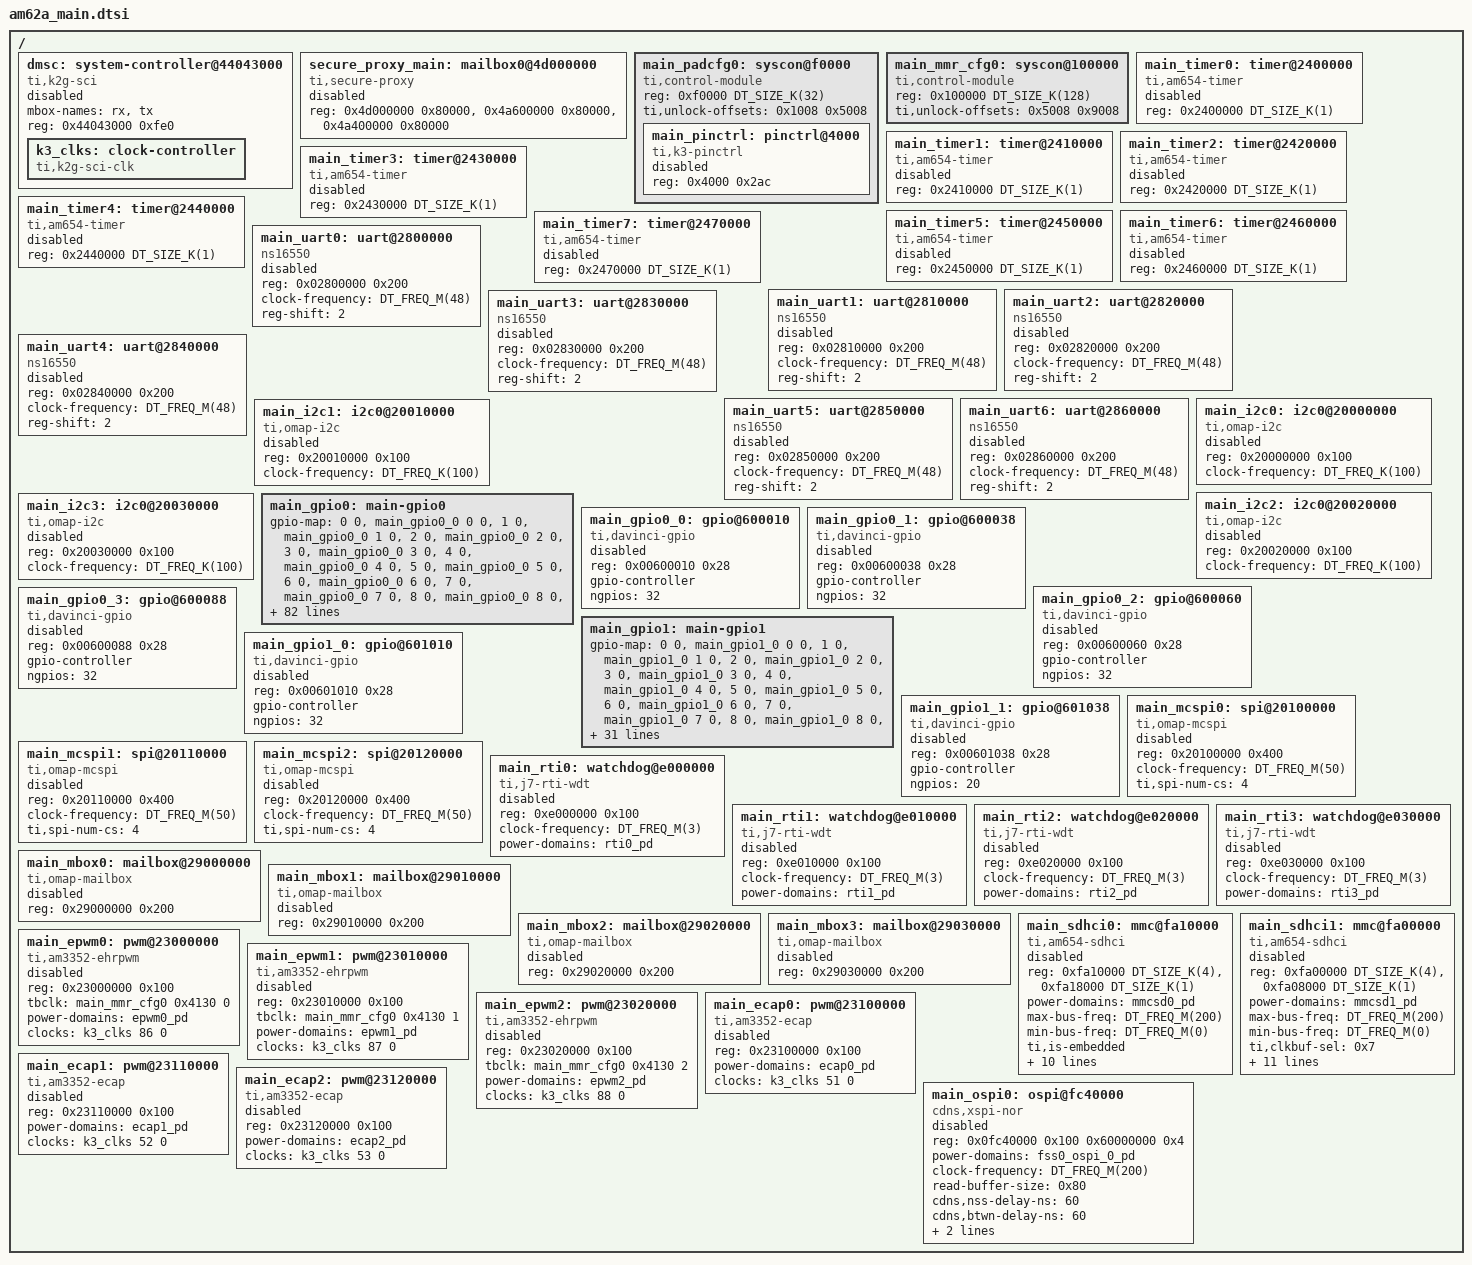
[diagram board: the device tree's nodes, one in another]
/*
 * Copyright (c) 2026 Texas Instruments Incorporated
 *
 * SPDX-License-Identifier: Apache-2.0
 */

#include <freq.h>
#include "am62a_main_power_domains.dtsi"

/ {
	#address-cells = <1>;
	#size-cells = <1>;

	dmsc: system-controller@44043000 {
		compatible = "ti,k2g-sci";
		mbox-names = "rx", "tx";
		reg-names = "debug_messages";
		reg = <0x44043000 0xfe0>;
		status = "disabled";

		k3_clks: clock-controller {
			compatible = "ti,k2g-sci-clk";
			#clock-cells = <2>;
		};
	};

	secure_proxy_main: mailbox0@4d000000 {
		compatible = "ti,secure-proxy";
		reg-names = "target_data", "rt", "scfg";
		reg = <0x4d000000 0x80000>, <0x4a600000 0x80000>, <0x4a400000 0x80000>;
		#mbox-cells = <1>;
		status = "disabled";
	};

	main_padcfg0: syscon@f0000 {
		compatible = "ti,control-module";
		reg = <0xf0000 DT_SIZE_K(32)>;
		ranges = <0x00 0xf0000 DT_SIZE_K(32)>;
		ti,unlock-offsets = <0x1008 0x5008>;
		#address-cells = <1>;
		#size-cells = <1>;

		main_pinctrl: pinctrl@4000 {
			compatible = "ti,k3-pinctrl";
			reg = <0x4000 0x2ac>;
			status = "disabled";
		};
	};

	main_mmr_cfg0: syscon@100000 {
		compatible = "ti,control-module", "syscon";
		reg = <0x100000 DT_SIZE_K(128)>;
		ti,unlock-offsets = <0x5008 0x9008>;
		#address-cells = <1>;
		#size-cells = <1>;
		#epwm-tbclk-cells = <2>;
		#clksel-cells = <2>;
	};

	main_timer0: timer@2400000 {
		compatible = "ti,am654-timer";
		reg = <0x2400000 DT_SIZE_K(1)>;
		status = "disabled";
	};

	main_timer1: timer@2410000 {
		compatible = "ti,am654-timer";
		reg = <0x2410000 DT_SIZE_K(1)>;
		status = "disabled";
	};

	main_timer2: timer@2420000 {
		compatible = "ti,am654-timer";
		reg = <0x2420000 DT_SIZE_K(1)>;
		status = "disabled";
	};

	main_timer3: timer@2430000 {
		compatible = "ti,am654-timer";
		reg = <0x2430000 DT_SIZE_K(1)>;
		status = "disabled";
	};

	main_timer4: timer@2440000 {
		compatible = "ti,am654-timer";
		reg = <0x2440000 DT_SIZE_K(1)>;
		status = "disabled";
	};

	main_timer5: timer@2450000 {
		compatible = "ti,am654-timer";
		reg = <0x2450000 DT_SIZE_K(1)>;
		status = "disabled";
	};

	main_timer6: timer@2460000 {
		compatible = "ti,am654-timer";
		reg = <0x2460000 DT_SIZE_K(1)>;
		status = "disabled";
	};

	main_timer7: timer@2470000 {
		compatible = "ti,am654-timer";
		reg = <0x2470000 DT_SIZE_K(1)>;
		status = "disabled";
	};

	main_uart0: uart@2800000 {
		compatible = "ns16550";
		reg = <0x02800000 0x200>;
		clock-frequency = <DT_FREQ_M(48)>;
		reg-shift = <2>;
		status = "disabled";
	};

	main_uart1: uart@2810000 {
		compatible = "ns16550";
		reg = <0x02810000 0x200>;
		clock-frequency = <DT_FREQ_M(48)>;
		reg-shift = <2>;
		status = "disabled";
	};

	main_uart2: uart@2820000 {
		compatible = "ns16550";
		reg = <0x02820000 0x200>;
		clock-frequency = <DT_FREQ_M(48)>;
		reg-shift = <2>;
		status = "disabled";
	};

	main_uart3: uart@2830000 {
		compatible = "ns16550";
		reg = <0x02830000 0x200>;
		clock-frequency = <DT_FREQ_M(48)>;
		reg-shift = <2>;
		status = "disabled";
	};

	main_uart4: uart@2840000 {
		compatible = "ns16550";
		reg = <0x02840000 0x200>;
		clock-frequency = <DT_FREQ_M(48)>;
		reg-shift = <2>;
		status = "disabled";
	};

	main_uart5: uart@2850000 {
		compatible = "ns16550";
		reg = <0x02850000 0x200>;
		clock-frequency = <DT_FREQ_M(48)>;
		reg-shift = <2>;
		status = "disabled";
	};

	main_uart6: uart@2860000 {
		compatible = "ns16550";
		reg = <0x02860000 0x200>;
		clock-frequency = <DT_FREQ_M(48)>;
		reg-shift = <2>;
		status = "disabled";
	};

	main_i2c0: i2c0@20000000 {
		compatible = "ti,omap-i2c";
		reg = <0x20000000 0x100>;
		clock-frequency = <DT_FREQ_K(100)>;
		#address-cells = <1>;
		#size-cells = <0>;
		status = "disabled";
	};

	main_i2c1: i2c0@20010000 {
		compatible = "ti,omap-i2c";
		reg = <0x20010000 0x100>;
		clock-frequency = <DT_FREQ_K(100)>;
		#address-cells = <1>;
		#size-cells = <0>;
		status = "disabled";
	};

	main_i2c2: i2c0@20020000 {
		compatible = "ti,omap-i2c";
		reg = <0x20020000 0x100>;
		clock-frequency = <DT_FREQ_K(100)>;
		#address-cells = <1>;
		#size-cells = <0>;
		status = "disabled";
	};

	main_i2c3: i2c0@20030000 {
		compatible = "ti,omap-i2c";
		reg = <0x20030000 0x100>;
		clock-frequency = <DT_FREQ_K(100)>;
		#address-cells = <1>;
		#size-cells = <0>;
		status = "disabled";
	};

	main_gpio0: main-gpio0 {
		#gpio-cells = <2>;
		gpio-map = <0 0 &main_gpio0_0 0 0>, <1 0 &main_gpio0_0 1 0>,
			   <2 0 &main_gpio0_0 2 0>, <3 0 &main_gpio0_0 3 0>,
			   <4 0 &main_gpio0_0 4 0>, <5 0 &main_gpio0_0 5 0>,
			   <6 0 &main_gpio0_0 6 0>, <7 0 &main_gpio0_0 7 0>,
			   <8 0 &main_gpio0_0 8 0>, <9 0 &main_gpio0_0 9 0>,
			   <10 0 &main_gpio0_0 10 0>, <11 0 &main_gpio0_0 11 0>,
			   <12 0 &main_gpio0_0 12 0>, <13 0 &main_gpio0_0 13 0>,
			   <14 0 &main_gpio0_0 14 0>, <15 0 &main_gpio0_0 15 0>,
			   <16 0 &main_gpio0_0 16 0>, <17 0 &main_gpio0_0 17 0>,
			   <18 0 &main_gpio0_0 18 0>, <19 0 &main_gpio0_0 19 0>,
			   <20 0 &main_gpio0_0 20 0>, <21 0 &main_gpio0_0 21 0>,
			   <22 0 &main_gpio0_0 22 0>, <23 0 &main_gpio0_0 23 0>,
			   <24 0 &main_gpio0_0 24 0>, <25 0 &main_gpio0_0 25 0>,
			   <26 0 &main_gpio0_0 26 0>, <27 0 &main_gpio0_0 27 0>,
			   <28 0 &main_gpio0_0 28 0>, <29 0 &main_gpio0_0 29 0>,
			   <30 0 &main_gpio0_0 30 0>, <31 0 &main_gpio0_0 31 0>,
			   <32 0 &main_gpio0_1 0 0>, <33 0 &main_gpio0_1 1 0>,
			   <34 0 &main_gpio0_1 2 0>, <35 0 &main_gpio0_1 3 0>,
			   <36 0 &main_gpio0_1 4 0>, <37 0 &main_gpio0_1 5 0>,
			   <38 0 &main_gpio0_1 6 0>, <39 0 &main_gpio0_1 7 0>,
			   <40 0 &main_gpio0_1 8 0>, <41 0 &main_gpio0_1 9 0>,
			   <42 0 &main_gpio0_1 10 0>, <43 0 &main_gpio0_1 11 0>,
			   <44 0 &main_gpio0_1 12 0>, <45 0 &main_gpio0_1 13 0>,
			   <46 0 &main_gpio0_1 14 0>, <47 0 &main_gpio0_1 15 0>,
			   <48 0 &main_gpio0_1 16 0>, <49 0 &main_gpio0_1 17 0>,
			   <50 0 &main_gpio0_1 18 0>, <51 0 &main_gpio0_1 19 0>,
			   <52 0 &main_gpio0_1 20 0>, <53 0 &main_gpio0_1 21 0>,
			   <54 0 &main_gpio0_1 22 0>, <55 0 &main_gpio0_1 23 0>,
			   <56 0 &main_gpio0_1 24 0>, <57 0 &main_gpio0_1 25 0>,
			   <58 0 &main_gpio0_1 26 0>, <59 0 &main_gpio0_1 27 0>,
			   <60 0 &main_gpio0_1 28 0>, <61 0 &main_gpio0_1 29 0>,
			   <62 0 &main_gpio0_1 30 0>, <63 0 &main_gpio0_1 31 0>,
			   <64 0 &main_gpio0_2 0 0>, <65 0 &main_gpio0_2 1 0>,
			   <66 0 &main_gpio0_2 2 0>, <67 0 &main_gpio0_2 3 0>,
			   <68 0 &main_gpio0_2 4 0>, <69 0 &main_gpio0_2 5 0>,
			   <70 0 &main_gpio0_2 6 0>, <71 0 &main_gpio0_2 7 0>,
			   <72 0 &main_gpio0_2 8 0>, <73 0 &main_gpio0_2 9 0>,
			   <74 0 &main_gpio0_2 10 0>, <75 0 &main_gpio0_2 11 0>,
			   <76 0 &main_gpio0_2 12 0>, <77 0 &main_gpio0_2 13 0>,
			   <78 0 &main_gpio0_2 14 0>, <79 0 &main_gpio0_2 15 0>,
			   <80 0 &main_gpio0_2 16 0>, <81 0 &main_gpio0_2 17 0>,
			   <82 0 &main_gpio0_2 18 0>, <83 0 &main_gpio0_2 17 0>,
			   <84 0 &main_gpio0_2 20 0>, <85 0 &main_gpio0_2 21 0>,
			   <86 0 &main_gpio0_2 22 0>, <87 0 &main_gpio0_2 23 0>,
			   <88 0 &main_gpio0_2 24 0>, <89 0 &main_gpio0_2 25 0>,
			   <90 0 &main_gpio0_2 26 0>, <91 0 &main_gpio0_2 27 0>,
			   <92 0 &main_gpio0_2 28 0>, <93 0 &main_gpio0_2 29 0>,
			   <94 0 &main_gpio0_2 30 0>, <95 0 &main_gpio0_2 31 0>,
			   <96 0 &main_gpio0_3 0 0>, <97 0 &main_gpio0_3 1 0>,
			   <98 0 &main_gpio0_3 2 0>, <99 0 &main_gpio0_3 3 0>,
			   <100 0 &main_gpio0_3 4 0>, <101 0 &main_gpio0_3 5 0>,
			   <102 0 &main_gpio0_3 6 0>, <103 0 &main_gpio0_3 7 0>,
			   <104 0 &main_gpio0_3 8 0>, <105 0 &main_gpio0_3 9 0>,
			   <106 0 &main_gpio0_3 10 0>, <107 0 &main_gpio0_3 11 0>,
			   <108 0 &main_gpio0_3 12 0>, <109 0 &main_gpio0_3 13 0>,
			   <110 0 &main_gpio0_3 14 0>, <111 0 &main_gpio0_3 15 0>,
			   <112 0 &main_gpio0_3 16 0>, <113 0 &main_gpio0_3 17 0>,
			   <114 0 &main_gpio0_3 18 0>, <116 0 &main_gpio0_3 17 0>,
			   <116 0 &main_gpio0_3 20 0>, <117 0 &main_gpio0_3 21 0>,
			   <118 0 &main_gpio0_3 22 0>, <119 0 &main_gpio0_3 23 0>,
			   <120 0 &main_gpio0_3 24 0>, <121 0 &main_gpio0_3 25 0>,
			   <122 0 &main_gpio0_3 26 0>, <123 0 &main_gpio0_3 27 0>,
			   <124 0 &main_gpio0_3 28 0>, <125 0 &main_gpio0_3 29 0>,
			   <126 0 &main_gpio0_3 30 0>, <127 0 &main_gpio0_3 31 0>;
		gpio-map-mask = <0xffff 0x0>;
		gpio-map-pass-thru = <0x0 0x1>;
	};

	main_gpio0_0: gpio@600010 {
		compatible = "ti,davinci-gpio";
		reg = <0x00600010 0x28>;
		gpio-controller;
		#gpio-cells = <2>;
		ngpios = <32>;
		status = "disabled";
	};

	main_gpio0_1: gpio@600038 {
		compatible = "ti,davinci-gpio";
		reg = <0x00600038 0x28>;
		gpio-controller;
		#gpio-cells = <2>;
		ngpios = <32>;
		status = "disabled";
	};

	main_gpio0_2: gpio@600060 {
		compatible = "ti,davinci-gpio";
		reg = <0x00600060 0x28>;
		gpio-controller;
		#gpio-cells = <2>;
		ngpios = <32>;
		status = "disabled";
	};

	main_gpio0_3: gpio@600088 {
		compatible = "ti,davinci-gpio";
		reg = <0x00600088 0x28>;
		gpio-controller;
		#gpio-cells = <2>;
		ngpios = <32>;
		status = "disabled";
	};

	main_gpio1: main-gpio1 {
		#gpio-cells = <2>;
		gpio-map = <0 0 &main_gpio1_0 0 0>, <1 0 &main_gpio1_0 1 0>,
			   <2 0 &main_gpio1_0 2 0>, <3 0 &main_gpio1_0 3 0>,
			   <4 0 &main_gpio1_0 4 0>, <5 0 &main_gpio1_0 5 0>,
			   <6 0 &main_gpio1_0 6 0>, <7 0 &main_gpio1_0 7 0>,
			   <8 0 &main_gpio1_0 8 0>, <9 0 &main_gpio1_0 9 0>,
			   <10 0 &main_gpio1_0 10 0>, <11 0 &main_gpio1_0 11 0>,
			   <12 0 &main_gpio1_0 12 0>, <13 0 &main_gpio1_0 13 0>,
			   <14 0 &main_gpio1_0 14 0>, <15 0 &main_gpio1_0 15 0>,
			   <16 0 &main_gpio1_0 16 0>, <17 0 &main_gpio1_0 17 0>,
			   <18 0 &main_gpio1_0 18 0>, <19 0 &main_gpio1_0 19 0>,
			   <20 0 &main_gpio1_0 20 0>, <21 0 &main_gpio1_0 21 0>,
			   <22 0 &main_gpio1_0 22 0>, <23 0 &main_gpio1_0 23 0>,
			   <24 0 &main_gpio1_0 24 0>, <25 0 &main_gpio1_0 25 0>,
			   <26 0 &main_gpio1_0 26 0>, <27 0 &main_gpio1_0 27 0>,
			   <28 0 &main_gpio1_0 28 0>, <29 0 &main_gpio1_0 29 0>,
			   <30 0 &main_gpio1_0 30 0>, <31 0 &main_gpio1_0 31 0>,
			   <32 0 &main_gpio1_1 0 0>, <33 0 &main_gpio1_1 1 0>,
			   <34 0 &main_gpio1_1 2 0>, <35 0 &main_gpio1_1 3 0>,
			   <36 0 &main_gpio1_1 4 0>, <37 0 &main_gpio1_1 5 0>,
			   <38 0 &main_gpio1_1 6 0>, <39 0 &main_gpio1_1 7 0>,
			   <40 0 &main_gpio1_1 8 0>, <41 0 &main_gpio1_1 9 0>,
			   <42 0 &main_gpio1_1 10 0>, <43 0 &main_gpio1_1 11 0>,
			   <44 0 &main_gpio1_1 12 0>, <45 0 &main_gpio1_1 13 0>,
			   <46 0 &main_gpio1_1 14 0>, <47 0 &main_gpio1_1 15 0>,
			   <48 0 &main_gpio1_1 16 0>, <49 0 &main_gpio1_1 17 0>,
			   <50 0 &main_gpio1_1 18 0>, <51 0 &main_gpio1_1 19 0>;
		gpio-map-mask = <0xffff 0x0>;
		gpio-map-pass-thru = <0x0 0x1>;
	};

	main_gpio1_0: gpio@601010 {
		compatible = "ti,davinci-gpio";
		reg = <0x00601010 0x28>;
		gpio-controller;
		#gpio-cells = <2>;
		ngpios = <32>;
		status = "disabled";
	};

	main_gpio1_1: gpio@601038 {
		compatible = "ti,davinci-gpio";
		reg = <0x00601038 0x28>;
		gpio-controller;
		#gpio-cells = <2>;
		ngpios = <20>;
		status = "disabled";
	};

	main_mcspi0: spi@20100000 {
		compatible = "ti,omap-mcspi";
		reg = <0x20100000 0x400>;
		clock-frequency = <DT_FREQ_M(50)>;
		ti,spi-num-cs = <4>;
		#address-cells = <1>;
		#size-cells = <0>;
		status = "disabled";
	};

	main_mcspi1: spi@20110000 {
		compatible = "ti,omap-mcspi";
		reg = <0x20110000 0x400>;
		clock-frequency = <DT_FREQ_M(50)>;
		ti,spi-num-cs = <4>;
		#address-cells = <1>;
		#size-cells = <0>;
		status = "disabled";
	};

	main_mcspi2: spi@20120000 {
		compatible = "ti,omap-mcspi";
		reg = <0x20120000 0x400>;
		clock-frequency = <DT_FREQ_M(50)>;
		ti,spi-num-cs = <4>;
		#address-cells = <1>;
		#size-cells = <0>;
		status = "disabled";
	};

	main_rti0: watchdog@e000000 {
		compatible = "ti,j7-rti-wdt";
		reg = <0xe000000 0x100>;
		clock-frequency = <DT_FREQ_M(3)>;
		power-domains = <&rti0_pd>;
		status = "disabled";
	};

	main_rti1: watchdog@e010000 {
		compatible = "ti,j7-rti-wdt";
		reg = <0xe010000 0x100>;
		clock-frequency = <DT_FREQ_M(3)>;
		power-domains = <&rti1_pd>;
		status = "disabled";
	};

	main_rti2: watchdog@e020000 {
		compatible = "ti,j7-rti-wdt";
		reg = <0xe020000 0x100>;
		clock-frequency = <DT_FREQ_M(3)>;
		power-domains = <&rti2_pd>;
		status = "disabled";
	};

	main_rti3: watchdog@e030000 {
		compatible = "ti,j7-rti-wdt";
		reg = <0xe030000 0x100>;
		clock-frequency = <DT_FREQ_M(3)>;
		power-domains = <&rti3_pd>;
		status = "disabled";
	};

	/* users: wkup_r5fss0_0 */
	main_mbox0: mailbox@29000000 {
		compatible = "ti,omap-mailbox";
		reg = <0x29000000 0x200>;
		#mbox-cells = <1>;
		status = "disabled";
	};

	/* users: c7x_0 */
	main_mbox1: mailbox@29010000 {
		compatible = "ti,omap-mailbox";
		reg = <0x29010000 0x200>;
		#mbox-cells = <1>;
		status = "disabled";
	};

	/* users: mcu_r5fss0_0 */
	main_mbox2: mailbox@29020000 {
		compatible = "ti,omap-mailbox";
		reg = <0x29020000 0x200>;
		#mbox-cells = <1>;
		status = "disabled";
	};

	main_mbox3: mailbox@29030000 {
		compatible = "ti,omap-mailbox";
		reg = <0x29030000 0x200>;
		#mbox-cells = <1>;
		status = "disabled";
	};

	main_sdhci0: mmc@fa10000 {
		compatible = "ti,am654-sdhci";
		reg = <0xfa10000 DT_SIZE_K(4)>, <0xfa18000 DT_SIZE_K(1)>;
		reg-names = "host", "subsys";
		power-domains = <&mmcsd0_pd>;
		max-bus-freq = <DT_FREQ_M(200)>;
		min-bus-freq = <DT_FREQ_M(0)>;
		ti,is-embedded;
		ti,dll-present;
		ti,driver-strength-ohm = <50>;
		ti,clkbuf-sel = <0x7>;
		ti,trm-icp = <0x2>;
		mmc-hs200-1_8v;
		ti,otap-del-sel-hs200 = <0x7>;
		ti,otap-del-sel-ddr52 = <0x6>;
		ti,itap-del-sel-legacy = <0x10>;
		ti,itap-del-sel-hs = <0xa>;
		ti,itap-del-sel-ddr52 = <0x3>;
		status = "disabled";
	};

	main_sdhci1: mmc@fa00000 {
		compatible = "ti,am654-sdhci";
		reg = <0xfa00000 DT_SIZE_K(4)>, <0xfa08000 DT_SIZE_K(1)>;
		reg-names = "host", "subsys";
		power-domains = <&mmcsd1_pd>;
		max-bus-freq = <DT_FREQ_M(200)>;
		min-bus-freq = <DT_FREQ_M(0)>;
		ti,clkbuf-sel = <0x7>;
		ti,itap-del-sel-legacy = <0x0>;
		ti,itap-del-sel-hs = <0x0>;
		ti,itap-del-sel-sdr12 = <0x0>;
		ti,itap-del-sel-sdr25 = <0x0>;
		ti,otap-del-sel-legacy = <0x0>;
		ti,otap-del-sel-hs = <0x0>;
		ti,otap-del-sel-sdr12 = <0xf>;
		ti,otap-del-sel-sdr25 = <0xf>;
		ti,otap-del-sel-sdr50 = <0xc>;
		ti,otap-del-sel-sdr104 = <0x6>;
		ti,otap-del-sel-ddr50 = <0x9>;
		status = "disabled";
	};

	main_epwm0: pwm@23000000 {
		compatible = "ti,am3352-ehrpwm";
		reg = <0x23000000 0x100>;
		tbclk = <&main_mmr_cfg0 0x4130 0>;
		#pwm-cells = <3>;
		power-domains = <&epwm0_pd>;
		clocks = <&k3_clks 86 0>;
		status = "disabled";
	};

	main_epwm1: pwm@23010000 {
		compatible = "ti,am3352-ehrpwm";
		reg = <0x23010000 0x100>;
		tbclk = <&main_mmr_cfg0 0x4130 1>;
		#pwm-cells = <3>;
		power-domains = <&epwm1_pd>;
		clocks = <&k3_clks 87 0>;
		status = "disabled";
	};

	main_epwm2: pwm@23020000 {
		compatible = "ti,am3352-ehrpwm";
		reg = <0x23020000 0x100>;
		tbclk = <&main_mmr_cfg0 0x4130 2>;
		#pwm-cells = <3>;
		power-domains = <&epwm2_pd>;
		clocks = <&k3_clks 88 0>;
		status = "disabled";
	};

	main_ecap0: pwm@23100000 {
		compatible = "ti,am3352-ecap";
		reg = <0x23100000 0x100>;
		#pwm-cells = <3>;
		power-domains = <&ecap0_pd>;
		clocks = <&k3_clks 51 0>;
		status = "disabled";
	};

	main_ecap1: pwm@23110000 {
		compatible = "ti,am3352-ecap";
		reg = <0x23110000 0x100>;
		#pwm-cells = <3>;
		power-domains = <&ecap1_pd>;
		clocks = <&k3_clks 52 0>;
		status = "disabled";
	};

	main_ecap2: pwm@23120000 {
		compatible = "ti,am3352-ecap";
		reg = <0x23120000 0x100>;
		#pwm-cells = <3>;
		power-domains = <&ecap2_pd>;
		clocks = <&k3_clks 53 0>;
		status = "disabled";
	};

	main_ospi0: ospi@fc40000 {
		compatible = "cdns,xspi-nor";
		reg = <0x0fc40000 0x100 0x60000000 0x4>;
		reg-names = "base", "fifo";
		power-domains = <&fss0_ospi_0_pd>;
		clock-frequency = <DT_FREQ_M(200)>;
		#address-cells = <1>;
		#size-cells = <0>;
		read-buffer-size = <0x80>;
		cdns,nss-delay-ns = <60>;
		cdns,btwn-delay-ns = <60>;
		cdns,after-delay-ns = <60>;
		cdns,init-delay-ns = <60>;
		status = "disabled";
	};
};
